AUTOSAR XML (schema 00046)
package /ComponentTypes
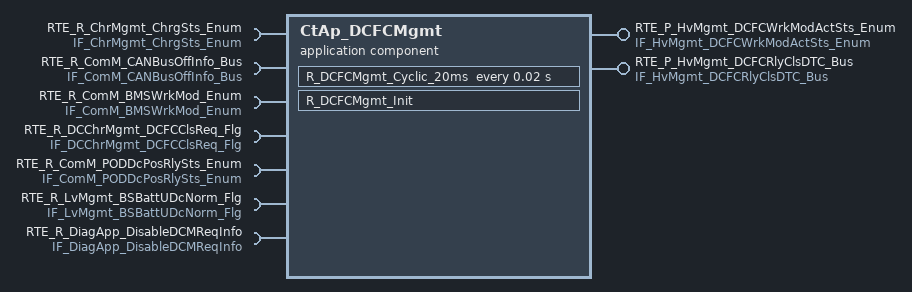
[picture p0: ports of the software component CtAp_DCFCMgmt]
  application sw component type CtAp_DCFCMgmt
    provide port RTE_P_HvMgmt_DCFCWrkModActSts_Enum: nonqueued-sender-com-spec{data-element=tec_HvMgmt_DCFCWrkModActSts_Enum, init-value=0}, provided-interface=IF_HvMgmt_DCFCWrkModActSts_Enum
    6 x require port:
      RTE_R_ChrMgmt_ChrgSts_Enum: nonqueued-receiver-com-spec{data-element=tec_ChrMgmt_ChrgSts_Enum, filter=data-filter-type=ALWAYS, init-value=0}, required-interface=IF_ChrMgmt_ChrgSts_Enum
      RTE_R_ComM_CANBusOffInfo_Bus: required-interface=IF_ComM_CANBusOffInfo_Bus
        required-com-specs:
          data-element=tec_ComM_EPTCANBusOffInfo_Bus, filter=data-filter-type=ALWAYS, init-value=fields=[ComM_MonStatEPTCANBusOffInfo:0, ComM_MonResEPTCANBusOffInfo:0, ComM_ErrStatEPTCANBusOffInfo:0, ComM_ErrResEPTCANBusOffInfo:0]
          data-element=tec_ComM_CHCANBusOffInfo_Bus, filter=data-filter-type=ALWAYS, init-value=fields=[ComM_MonStatCHCANBusOffInfo:0, ComM_MonResCHCANBusOffInfo:0, ComM_ErrStatCHCANBusOffInfo:0, ComM_ErrResCHCANBusOffInfo:0]
          data-element=tec_ComM_EPTCANBusOffDTCInfo_Bus, filter=data-filter-type=ALWAYS, init-value=fields=[ComM_MonStatEPTCANBusOffDTCInfo:0, ComM_MonResEPTCANBusOffDTCInfo:0, ComM_ErrStatEPTCANBusOffDTCInfo:0, ComM_ErrResEPTCANBusOffDTCInfo:0]
          data-element=tec_ComM_CHCANBusOffDTCInfo_Bus, filter=data-filter-type=ALWAYS, init-value=fields=[ComM_MonStatCHCANBusOffDTCInfo:0, ComM_MonResCHCANBusOffDTCInfo:0, ComM_ErrStatCHCANBusOffDTCInfo:0, ComM_ErrResCHCANBusOffDTCInfo:0]
          data-element=tec_ComM_DCCANBusOffDTCInfo_Bus, init-value=fields=[ComM_MonStatDCCANDTCBusOffInfo:0, ComM_MonResDCCANDTCBusOffInfo:0, ComM_ErrStatDCCANDTCBusOffInfo:0, ComM_ErrResDCCANDTCBusOffInfo:0]
          data-element=tec_ComM_DCCANBusOffInfo_Bus, init-value=fields=[ComM_MonStatDCCANBusOffInfo:0, ComM_MonResDCCANBusOffInfo:0, ComM_ErrStatDCCANBusOffInfo:0, ComM_ErrResDCCANBusOffInfo:0]
      RTE_R_ComM_BMSWrkMod_Enum: nonqueued-receiver-com-spec{data-element=tec_ComM_BMSWrkMod_Enum, filter=data-filter-type=ALWAYS, init-value=0}, required-interface=IF_ComM_BMSWrkMod_Enum
      RTE_R_DCChrMgmt_DCFCClsReq_Flg: nonqueued-receiver-com-spec{data-element=tec_DCChrMgmt_DCFCClsReq_Flg, filter=data-filter-type=ALWAYS, init-value=0}, required-interface=IF_DCChrMgmt_DCFCClsReq_Flg
      RTE_R_ComM_PODDcPosRlySts_Enum: nonqueued-receiver-com-spec{data-element=tec_ComM_PODDcPosRlySts_Enum, filter=data-filter-type=ALWAYS, init-value=0}, required-interface=IF_ComM_PODDcPosRlySts_Enum
      RTE_R_LvMgmt_BSBattUDcNorm_Flg: nonqueued-receiver-com-spec{data-element=tec_LvMgmt_BSBattUDcNorm_Flg, filter=data-filter-type=ALWAYS, init-value=0}, required-interface=IF_LvMgmt_BSBattUDcNorm_Flg
    provide port RTE_P_HvMgmt_DCFCRlyClsDTC_Bus: nonqueued-sender-com-spec{data-element=tec_HvMgmt_DCFCRlyClsDTC_Bus, init-value=fields=[HvMgmt_MonStatDCFCRlyClsDTC:0, HvMgmt_MonResDCFCRlyClsDTC:0, HvMgmt_ErrStatDCFCRlyClsDTC:0, HvMgmt_ErrResDCFCRlyClsDTC:0]}, provided-interface=IF_HvMgmt_DCFCRlyClsDTC_Bus
    require port RTE_R_DiagApp_DisableDCMReqInfo: nonqueued-receiver-com-spec{data-element=tec_DiagApp_DisableDCMReqInfo, filter=data-filter-type=ALWAYS, init-value=0}, required-interface=IF_DiagApp_DisableDCMReqInfo
    behavior CtAp_DCFCMgmt_InternalBehavior
      timing event TMT_R_DCFCMgmt_Cyclic_20ms: start-on-event=R_DCFCMgmt_Cyclic_20ms, period=0.02
      init event CtAp_DCFCMgmt_InitEvent: start-on-event=R_DCFCMgmt_Init
      runnable R_DCFCMgmt_Cyclic_20ms
        data-receive-point-by-arguments:
          7 x access:
            REC_RTE_R_ChrMgmt_ChrgSts_Enum_tec_ChrMgmt_ChrgSts_Enum: accessed-variable=RTE_R_ChrMgmt_ChrgSts_Enum.tec_ChrMgmt_ChrgSts_Enum
            REC_RTE_R_ComM_BMSWrkMod_Enum_tec_ComM_BMSWrkMod_Enum: accessed-variable=RTE_R_ComM_BMSWrkMod_Enum.tec_ComM_BMSWrkMod_Enum
            REC_RTE_R_ComM_CANBusOffInfo_Bus_tec_ComM_EPTCANBusOffInfo_Bus: accessed-variable=RTE_R_ComM_CANBusOffInfo_Bus.tec_ComM_EPTCANBusOffInfo_Bus
            REC_RTE_R_ComM_PODDcPosRlySts_Enum_tec_ComM_PODDcPosRlySts_Enum: accessed-variable=RTE_R_ComM_PODDcPosRlySts_Enum.tec_ComM_PODDcPosRlySts_Enum
            REC_RTE_R_DCChrMgmt_DCFCClsReq_Flg_tec_DCChrMgmt_DCFCClsReq_Flg: accessed-variable=RTE_R_DCChrMgmt_DCFCClsReq_Flg.tec_DCChrMgmt_DCFCClsReq_Flg
            REC_RTE_R_LvMgmt_BSBattUDcNorm_Flg_tec_LvMgmt_BSBattUDcNorm_Flg: accessed-variable=RTE_R_LvMgmt_BSBattUDcNorm_Flg.tec_LvMgmt_BSBattUDcNorm_Flg
            REC_RTE_R_DiagApp_DisableDCMReqInfo_tec_DiagApp_DisableDCMReqInfo: accessed-variable=RTE_R_DiagApp_DisableDCMReqInfo.tec_DiagApp_DisableDCMReqInfo
        data-send-points:
          access SEND_RTE_P_HvMgmt_DCFCRlyClsDTC_Bus_tec_HvMgmt_DCFCRlyClsDTC_Bus: accessed-variable=RTE_P_HvMgmt_DCFCRlyClsDTC_Bus.tec_HvMgmt_DCFCRlyClsDTC_Bus
          access SEND_RTE_P_HvMgmt_DCFCWrkModActSts_Enum_tec_HvMgmt_DCFCWrkModActSts_Enum: accessed-variable=RTE_P_HvMgmt_DCFCWrkModActSts_Enum.tec_HvMgmt_DCFCWrkModActSts_Enum
      runnable R_DCFCMgmt_Init
  swc implementation CtAp_DCFCMgmt_Implementation: behavior=CtAp_DCFCMgmt_InternalBehavior
